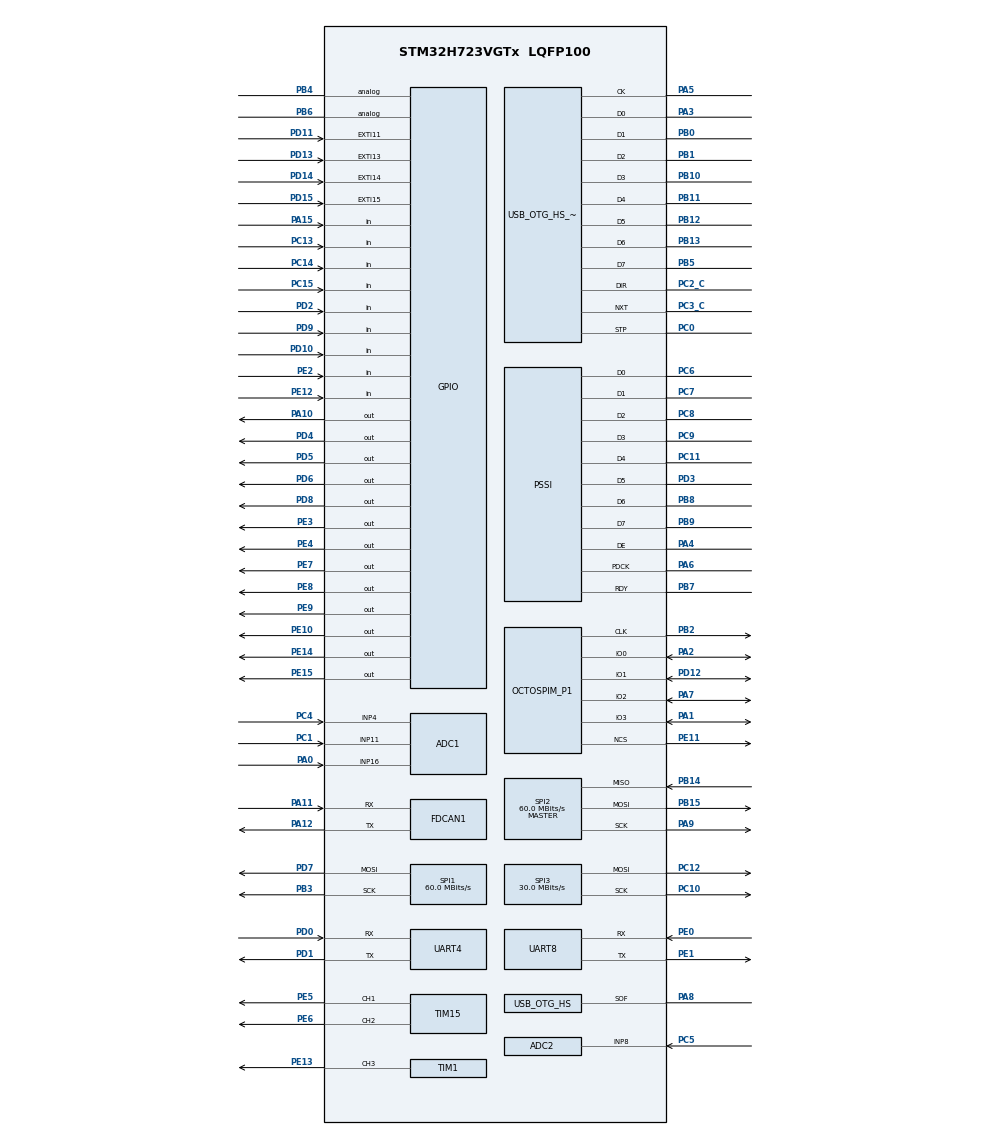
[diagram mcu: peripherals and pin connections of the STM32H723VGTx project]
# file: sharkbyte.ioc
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ADC1.Channel-0\#ChannelRegularConversion=ADC_CHANNEL_4
ADC1.ClockPrescaler=ADC_CLOCK_ASYNC_DIV4
ADC1.ExternalTrigConv=ADC_EXTERNALTRIG_T1_TRGO
ADC1.NbrOfConversionFlag=1
ADC1.OffsetNumber-0\#ChannelRegularConversion=ADC_OFFSET_NONE
ADC1.OffsetSignedSaturation-0\#ChannelRegularConversion=DISABLE
ADC1.Rank-0\#ChannelRegularConversion=1
ADC1.SamplingTime-0\#ChannelRegularConversion=ADC_SAMPLETIME_1CYCLE_5
ADC1.master=1
ADC2.Channel-3\#ChannelRegularConversion=ADC_CHANNEL_8
ADC2.ClockPrescaler=ADC_CLOCK_ASYNC_DIV4
ADC2.ExternalTrigConv=ADC_EXTERNALTRIG_T1_TRGO
ADC2.NbrOfConversionFlag=1
ADC2.OffsetNumber-3\#ChannelRegularConversion=ADC_OFFSET_NONE
ADC2.OffsetSignedSaturation-3\#ChannelRegularConversion=DISABLE
ADC2.Rank-3\#ChannelRegularConversion=1
ADC2.SamplingTime-3\#ChannelRegularConversion=ADC_SAMPLETIME_1CYCLE_5
CORTEX_M7.default_mode_Activation=1
Dma.ADC1.0.Direction=DMA_PERIPH_TO_MEMORY
Dma.ADC1.0.EventEnable=DISABLE
Dma.ADC1.0.FIFOMode=DMA_FIFOMODE_DISABLE
Dma.ADC1.0.Instance=DMA1_Stream0
Dma.ADC1.0.MemDataAlignment=DMA_MDATAALIGN_HALFWORD
Dma.ADC1.0.MemInc=DMA_MINC_ENABLE
Dma.ADC1.0.Mode=DMA_CIRCULAR
Dma.ADC1.0.PeriphDataAlignment=DMA_PDATAALIGN_HALFWORD
Dma.ADC1.0.PeriphInc=DMA_PINC_DISABLE
Dma.ADC1.0.Polarity=HAL_DMAMUX_REQ_GEN_RISING
Dma.ADC1.0.Priority=DMA_PRIORITY_HIGH
Dma.ADC1.0.RequestNumber=1
Dma.ADC1.0.SignalID=NONE
Dma.ADC1.0.SyncEnable=DISABLE
Dma.ADC1.0.SyncPolarity=HAL_DMAMUX_SYNC_NO_EVENT
Dma.ADC1.0.SyncRequestNumber=1
Dma.ADC1.0.SyncSignalID=NONE
Dma.Request0=ADC1
Dma.Request1=SPI1_TX
Dma.Request2=SPI2_RX
Dma.Request3=SPI2_TX
Dma.Request4=SPI3_TX
Dma.SPI1_TX.1.Direction=DMA_MEMORY_TO_PERIPH
Dma.SPI1_TX.1.EventEnable=DISABLE
Dma.SPI1_TX.1.FIFOMode=DMA_FIFOMODE_DISABLE
Dma.SPI1_TX.1.Instance=DMA1_Stream1
Dma.SPI1_TX.1.MemDataAlignment=DMA_MDATAALIGN_BYTE
Dma.SPI1_TX.1.MemInc=DMA_MINC_ENABLE
Dma.SPI1_TX.1.Mode=DMA_NORMAL
Dma.SPI1_TX.1.PeriphDataAlignment=DMA_PDATAALIGN_BYTE
Dma.SPI1_TX.1.PeriphInc=DMA_PINC_DISABLE
Dma.SPI1_TX.1.Polarity=HAL_DMAMUX_REQ_GEN_RISING
Dma.SPI1_TX.1.Priority=DMA_PRIORITY_MEDIUM
Dma.SPI1_TX.1.RequestNumber=1
Dma.SPI1_TX.1.SignalID=NONE
Dma.SPI1_TX.1.SyncEnable=DISABLE
Dma.SPI1_TX.1.SyncPolarity=HAL_DMAMUX_SYNC_NO_EVENT
Dma.SPI1_TX.1.SyncRequestNumber=1
Dma.SPI1_TX.1.SyncSignalID=NONE
Dma.SPI2_RX.2.Direction=DMA_PERIPH_TO_MEMORY
Dma.SPI2_RX.2.EventEnable=DISABLE
Dma.SPI2_RX.2.FIFOMode=DMA_FIFOMODE_DISABLE
Dma.SPI2_RX.2.Instance=DMA1_Stream2
Dma.SPI2_RX.2.MemDataAlignment=DMA_MDATAALIGN_BYTE
Dma.SPI2_RX.2.MemInc=DMA_MINC_ENABLE
Dma.SPI2_RX.2.Mode=DMA_NORMAL
Dma.SPI2_RX.2.PeriphDataAlignment=DMA_PDATAALIGN_BYTE
Dma.SPI2_RX.2.PeriphInc=DMA_PINC_DISABLE
Dma.SPI2_RX.2.Polarity=HAL_DMAMUX_REQ_GEN_RISING
Dma.SPI2_RX.2.Priority=DMA_PRIORITY_HIGH
Dma.SPI2_RX.2.RequestNumber=1
Dma.SPI2_RX.2.SignalID=NONE
Dma.SPI2_RX.2.SyncEnable=DISABLE
Dma.SPI2_RX.2.SyncPolarity=HAL_DMAMUX_SYNC_NO_EVENT
Dma.SPI2_RX.2.SyncRequestNumber=1
Dma.SPI2_RX.2.SyncSignalID=NONE
Dma.SPI2_TX.3.Direction=DMA_MEMORY_TO_PERIPH
Dma.SPI2_TX.3.EventEnable=DISABLE
Dma.SPI2_TX.3.FIFOMode=DMA_FIFOMODE_DISABLE
Dma.SPI2_TX.3.Instance=DMA1_Stream3
Dma.SPI2_TX.3.MemDataAlignment=DMA_MDATAALIGN_BYTE
Dma.SPI2_TX.3.MemInc=DMA_MINC_ENABLE
Dma.SPI2_TX.3.Mode=DMA_NORMAL
Dma.SPI2_TX.3.PeriphDataAlignment=DMA_PDATAALIGN_BYTE
Dma.SPI2_TX.3.PeriphInc=DMA_PINC_DISABLE
Dma.SPI2_TX.3.Polarity=HAL_DMAMUX_REQ_GEN_RISING
Dma.SPI2_TX.3.Priority=DMA_PRIORITY_HIGH
Dma.SPI2_TX.3.RequestNumber=1
Dma.SPI2_TX.3.SignalID=NONE
Dma.SPI2_TX.3.SyncEnable=DISABLE
Dma.SPI2_TX.3.SyncPolarity=HAL_DMAMUX_SYNC_NO_EVENT
Dma.SPI2_TX.3.SyncRequestNumber=1
Dma.SPI2_TX.3.SyncSignalID=NONE
Dma.SPI3_TX.4.Direction=DMA_MEMORY_TO_PERIPH
Dma.SPI3_TX.4.EventEnable=DISABLE
Dma.SPI3_TX.4.FIFOMode=DMA_FIFOMODE_DISABLE
Dma.SPI3_TX.4.Instance=DMA1_Stream4
Dma.SPI3_TX.4.MemDataAlignment=DMA_MDATAALIGN_BYTE
Dma.SPI3_TX.4.MemInc=DMA_MINC_ENABLE
Dma.SPI3_TX.4.Mode=DMA_NORMAL
Dma.SPI3_TX.4.PeriphDataAlignment=DMA_PDATAALIGN_BYTE
Dma.SPI3_TX.4.PeriphInc=DMA_PINC_DISABLE
Dma.SPI3_TX.4.Polarity=HAL_DMAMUX_REQ_GEN_RISING
Dma.SPI3_TX.4.Priority=DMA_PRIORITY_LOW
Dma.SPI3_TX.4.RequestNumber=1
Dma.SPI3_TX.4.SignalID=NONE
Dma.SPI3_TX.4.SyncEnable=DISABLE
Dma.SPI3_TX.4.SyncPolarity=HAL_DMAMUX_SYNC_NO_EVENT
Dma.SPI3_TX.4.SyncRequestNumber=1
Dma.SPI3_TX.4.SyncSignalID=NONE
FDCAN1.CalculateBaudRateNominal=2291666
FDCAN1.CalculateTimeBitNominal=436
FDCAN1.CalculateTimeQuantumNominal=145.45454545454547
FREERTOS.Tasks01=defaultTask,24,512,StartDefaultTask,Default,NULL,Dynamic,NULL,NULL;task_Acquisitio,40,1024,StartAcquisition,Default,NULL,Dynamic,NULL,NULL;task_Comms,32,2048,StartComms,Default,NULL,Dynamic,NULL,NULL;task_Control,24,1024,StartControl,Default,NULL,Dynamic,NULL,NULL;task_GUI,8,4096,StartGUI,Default,NULL,Dynamic,NULL,NULL
FREERTOS.configTOTAL_HEAP_SIZE=65536
FREERTOS.configUSE_NEWLIB_REENTRANT=1
Mcu.Family=STM32H7
Mcu.Name=STM32H723VGTx
Mcu.Package=LQFP100
NVIC.DMA1_Stream0_IRQn=true\:5\:0\:false\:false\:true\:true\:false\:true\:true
NVIC.DMA1_Stream1_IRQn=true\:5\:0\:false\:false\:true\:true\:false\:true\:true
NVIC.DMA1_Stream2_IRQn=true\:5\:0\:false\:false\:true\:true\:false\:true\:true
NVIC.DMA1_Stream3_IRQn=true\:5\:0\:false\:false\:true\:true\:false\:true\:true
NVIC.DMA1_Stream4_IRQn=true\:5\:0\:false\:false\:true\:true\:false\:true\:true
NVIC.EXTI15_10_IRQn=true\:5\:0\:false\:false\:true\:true\:true\:true\:true
NVIC.FDCAN1_IT0_IRQn=true\:5\:0\:false\:false\:true\:true\:true\:true\:true
NVIC.OTG_HS_IRQn=true\:5\:0\:false\:false\:true\:true\:false\:true\:true
NVIC.PriorityGroup=NVIC_PRIORITYGROUP_4
NVIC.SPI1_IRQn=true\:5\:0\:false\:false\:true\:true\:false\:true\:true
NVIC.SPI2_IRQn=true\:5\:0\:false\:false\:true\:true\:false\:true\:true
NVIC.SPI3_IRQn=true\:5\:0\:false\:false\:true\:true\:false\:true\:true
NVIC.TIM6_DAC_IRQn=true\:15\:0\:true\:false\:true\:false\:false\:true\:true
NVIC.TIM7_IRQn=true\:5\:0\:false\:false\:true\:true\:true\:true\:true
NVIC.TimeBase=TIM6_DAC_IRQn
NVIC.TimeBaseIP=TIM6
PA0.Mode=IN16-Single-Ended
PA0.Signal=ADC1_INP16
PA1.Mode=OCTOSPI1_IOL_Port1L
PA1.Signal=OCTOSPIM_P1_IO3
PA10.Signal=GPIO_Output
PA11.Mode=FDCAN_Activate
PA11.Signal=FDCAN1_RX
PA12.Mode=FDCAN_Activate
PA12.Signal=FDCAN1_TX
PA13(JTMS/SWDIO).Mode=Serial_Wire
PA13(JTMS/SWDIO).Signal=DEBUG_JTMS-SWDIO
PA14(JTCK/SWCLK).Mode=Serial_Wire
PA14(JTCK/SWCLK).Signal=DEBUG_JTCK-SWCLK
PA15(JTDI).Signal=GPIO_Input
PA2.Mode=OCTOSPI1_IOL_Port1L
PA2.Signal=OCTOSPIM_P1_IO0
PA3.GPIO_Mode=GPIO_MODE_AF_PP
PA3.GPIO_PuPd=GPIO_NOPULL
PA3.GPIO_Speed_Only_High=GPIO_SPEED_FREQ_VERY_HIGH
PA3.Mode=Device_HS
PA3.Signal=USB_OTG_HS_ULPI_D0
PA4.Mode=PSSI_8
PA4.Signal=PSSI_DE
PA5.GPIO_Mode=GPIO_MODE_AF_PP
PA5.GPIO_PuPd=GPIO_NOPULL
PA5.GPIO_Speed_Only_High=GPIO_SPEED_FREQ_VERY_HIGH
PA5.Mode=Device_HS
PA5.Signal=USB_OTG_HS_ULPI_CK
PA6.Mode=PSSI_8
PA6.Signal=PSSI_PDCK
PA7.Mode=OCTOSPI1_IOL_Port1L
PA7.Signal=OCTOSPIM_P1_IO2
PA8.GPIO_Mode=GPIO_MODE_AF_PP
PA8.GPIO_PuPd=GPIO_NOPULL
PA8.GPIO_Speed=GPIO_SPEED_FREQ_VERY_HIGH
PA8.GPIO_Speed_Only_High=GPIO_SPEED_FREQ_VERY_HIGH
PA8.Mode=Activate_SOF_FS
PA8.Signal=USB_OTG_HS_SOF
PA9.Mode=Full_Duplex_Master
PA9.Signal=SPI2_SCK
PB0.GPIO_Mode=GPIO_MODE_AF_PP
PB0.GPIO_PuPd=GPIO_NOPULL
PB0.GPIO_Speed_Only_High=GPIO_SPEED_FREQ_VERY_HIGH
PB0.Mode=Device_HS
PB0.Signal=USB_OTG_HS_ULPI_D1
PB1.GPIO_Mode=GPIO_MODE_AF_PP
PB1.GPIO_PuPd=GPIO_NOPULL
PB1.GPIO_Speed_Only_High=GPIO_SPEED_FREQ_VERY_HIGH
PB1.Mode=Device_HS
PB1.Signal=USB_OTG_HS_ULPI_D2
PB10.GPIO_Mode=GPIO_MODE_AF_PP
PB10.GPIO_PuPd=GPIO_NOPULL
PB10.GPIO_Speed_Only_High=GPIO_SPEED_FREQ_VERY_HIGH
PB10.Mode=Device_HS
PB10.Signal=USB_OTG_HS_ULPI_D3
PB11.GPIO_Mode=GPIO_MODE_AF_PP
PB11.GPIO_PuPd=GPIO_NOPULL
PB11.GPIO_Speed_Only_High=GPIO_SPEED_FREQ_VERY_HIGH
PB11.Mode=Device_HS
PB11.Signal=USB_OTG_HS_ULPI_D4
PB12.GPIO_Mode=GPIO_MODE_AF_PP
PB12.GPIO_PuPd=GPIO_NOPULL
PB12.GPIO_Speed_Only_High=GPIO_SPEED_FREQ_VERY_HIGH
PB12.Mode=Device_HS
PB12.Signal=USB_OTG_HS_ULPI_D5
PB13.GPIO_Mode=GPIO_MODE_AF_PP
PB13.GPIO_PuPd=GPIO_NOPULL
PB13.GPIO_Speed_Only_High=GPIO_SPEED_FREQ_VERY_HIGH
PB13.Mode=Device_HS
PB13.Signal=USB_OTG_HS_ULPI_D6
PB14.Mode=Full_Duplex_Master
PB14.Signal=SPI2_MISO
PB15.Mode=Full_Duplex_Master
PB15.Signal=SPI2_MOSI
PB2.Mode=O1_P1_CLK
PB2.Signal=OCTOSPIM_P1_CLK
PB3(JTDO/TRACESWO).Mode=TX_Only_Simplex_Unidirect_Master
PB3(JTDO/TRACESWO).Signal=SPI1_SCK
PB4(NJTRST).Signal=GPIO_Analog
PB5.GPIO_Mode=GPIO_MODE_AF_PP
PB5.GPIO_PuPd=GPIO_NOPULL
PB5.GPIO_Speed_Only_High=GPIO_SPEED_FREQ_VERY_HIGH
PB5.Mode=Device_HS
PB5.Signal=USB_OTG_HS_ULPI_D7
PB6.Signal=GPIO_Analog
PB7.Mode=PSSI_8
PB7.Signal=PSSI_RDY
PB8.Mode=PSSI_8
PB8.Signal=PSSI_D6
PB9.Mode=PSSI_8
PB9.Signal=PSSI_D7
PC0.GPIO_Mode=GPIO_MODE_AF_PP
PC0.GPIO_PuPd=GPIO_NOPULL
PC0.GPIO_Speed_Only_High=GPIO_SPEED_FREQ_VERY_HIGH
PC0.Mode=Device_HS
PC0.Signal=USB_OTG_HS_ULPI_STP
PC1.Signal=ADCx_INP11
PC10.Mode=TX_Only_Simplex_Unidirect_Master
PC10.Signal=SPI3_SCK
PC11.Mode=PSSI_8
PC11.Signal=PSSI_D4
PC12.Mode=TX_Only_Simplex_Unidirect_Master
PC12.Signal=SPI3_MOSI
PC13.Signal=GPIO_Input
PC14-OSC32_IN.Signal=GPIO_Input
PC15-OSC32_OUT.Signal=GPIO_Input
PC2_C.GPIO_Mode=GPIO_MODE_AF_PP
PC2_C.GPIO_PuPd=GPIO_NOPULL
PC2_C.GPIO_Speed_Only_High=GPIO_SPEED_FREQ_VERY_HIGH
PC2_C.Mode=Device_HS
PC2_C.Signal=USB_OTG_HS_ULPI_DIR
PC3_C.GPIO_Mode=GPIO_MODE_AF_PP
PC3_C.GPIO_PuPd=GPIO_NOPULL
PC3_C.GPIO_Speed_Only_High=GPIO_SPEED_FREQ_VERY_HIGH
PC3_C.Mode=Device_HS
PC3_C.Signal=USB_OTG_HS_ULPI_NXT
PC4.Signal=ADCx_INP4
PC5.Signal=ADCx_INP8
PC6.Mode=PSSI_8
PC6.Signal=PSSI_D0
PC7.Mode=PSSI_8
PC7.Signal=PSSI_D1
PC8.Mode=PSSI_8
PC8.Signal=PSSI_D2
PC9.Mode=PSSI_8
PC9.Signal=PSSI_D3
PD0.Mode=Asynchronous
PD0.Signal=UART4_RX
PD1.Mode=Asynchronous
PD1.Signal=UART4_TX
PD10.Signal=GPIO_Input
PD11.Signal=GPXTI11
PD12.Mode=OCTOSPI1_IOL_Port1L
PD12.Signal=OCTOSPIM_P1_IO1
PD13.GPIO_ModeDefaultEXTI=GPIO_MODE_IT_RISING_FALLING
PD13.Signal=GPXTI13
PD14.GPIO_ModeDefaultEXTI=GPIO_MODE_IT_RISING_FALLING
PD14.Signal=GPXTI14
PD15.GPIO_ModeDefaultEXTI=GPIO_MODE_IT_RISING_FALLING
PD15.Signal=GPXTI15
PD2.Signal=GPIO_Input
PD3.Mode=PSSI_8
PD3.Signal=PSSI_D5
PD4.Signal=GPIO_Output
PD5.Signal=GPIO_Output
PD6.Signal=GPIO_Output
PD7.Mode=TX_Only_Simplex_Unidirect_Master
PD7.Signal=SPI1_MOSI
PD8.Signal=GPIO_Output
PD9.Signal=GPIO_Input
PE0.Mode=Asynchronous
PE0.Signal=UART8_RX
PE1.Mode=Asynchronous
PE1.Signal=UART8_TX
PE10.Signal=GPIO_Output
PE11.Mode=OCTOSPI1_Port1_NCS
PE11.Signal=OCTOSPIM_P1_NCS
PE12.Signal=GPIO_Input
PE13.Signal=S_TIM1_CH3
PE14.Signal=GPIO_Output
PE15.Signal=GPIO_Output
PE2.Signal=GPIO_Input
PE3.Signal=GPIO_Output
PE4.Signal=GPIO_Output
PE5.Signal=S_TIM15_CH1
PE6.Signal=S_TIM15_CH2
PE7.Signal=GPIO_Output
PE8.Signal=GPIO_Output
PE9.Signal=GPIO_Output
PH0-OSC_IN.Mode=HSE-External-Oscillator
PH0-OSC_IN.Signal=RCC_OSC_IN
PH1-OSC_OUT.Mode=HSE-External-Oscillator
PH1-OSC_OUT.Signal=RCC_OSC_OUT
PSSI.BusWidth=HAL_PSSI_8LINES
ProjectManager.HeapSize=0x2000
ProjectManager.StackSize=0x2000
ProjectManager.TargetToolchain=CMake
RCC.ADCFreq_Value=120000000
RCC.APB1Freq_Value=137500000
RCC.APB2Freq_Value=137500000
RCC.APB3Freq_Value=137500000
RCC.APB4Freq_Value=137500000
RCC.CortexFreq_Value=550000000
RCC.D1PPRE=RCC_APB3_DIV2
RCC.D2PPRE1=RCC_APB1_DIV2
RCC.D2PPRE2=RCC_APB2_DIV2
RCC.D3PPRE=RCC_APB4_DIV2
RCC.DIVM1=5
RCC.DIVM2=5
RCC.DIVM3=5
RCC.DIVN1=110
RCC.DIVN2=96
RCC.DIVN3=96
RCC.DIVP1=1
RCC.DIVP2=4
RCC.DIVQ1=5
RCC.DIVQ2=6
RCC.DIVQ3=10
RCC.DIVR2=4
RCC.DIVR3=5
RCC.FMCCLockSelection=RCC_FMCCLKSOURCE_PLL
RCC.HCLKFreq_Value=275000000
RCC.HPRE=RCC_HCLK_DIV2
RCC.HSE_VALUE=25000000
RCC.PLL2FRACN=0
RCC.PLL3FRACN=0
RCC.PLLFRACN=0
RCC.PLLSourceVirtual=RCC_PLLSOURCE_HSE
RCC.QSPICLockSelection=RCC_OSPICLKSOURCE_PLL2
RCC.SPI123CLockSelection=RCC_SPI123CLKSOURCE_PLL2
RCC.SYSCLKFreq_VALUE=550000000
RCC.SYSCLKSource=RCC_SYSCLKSOURCE_PLLCLK
RCC.USART234578CLockSelection=RCC_USART234578CLKSOURCE_PLL2
RCC.USBCLockSelection=RCC_USBCLKSOURCE_PLL3
RCC.USBFreq_Value=48000000
SH.ADCx_INP11.0=ADC1_INP11,IN11-Single-Ended
SH.ADCx_INP4.0=ADC1_INP4,IN4-Single-Ended
SH.ADCx_INP8.0=ADC2_INP8,IN8-Single-Ended
SH.S_TIM15_CH1.0=TIM15_CH1,PWM Generation1 CH1
SH.S_TIM15_CH2.0=TIM15_CH2,PWM Generation2 CH2
SH.S_TIM1_CH3.0=TIM1_CH3,PWM Generation3 CH3
SPI1.BaudRatePrescaler=SPI_BAUDRATEPRESCALER_2
SPI1.CalculateBaudRate=60.0 MBits/s
SPI1.Direction=SPI_DIRECTION_2LINES_TXONLY
SPI1.Mode=SPI_MODE_MASTER
SPI1.VirtualType=VM_MASTER
SPI2.BaudRatePrescaler=SPI_BAUDRATEPRESCALER_2
SPI2.CalculateBaudRate=60.0 MBits/s
SPI2.Direction=SPI_DIRECTION_2LINES
SPI2.Mode=SPI_MODE_MASTER
SPI2.VirtualType=VM_MASTER
SPI3.BaudRatePrescaler=SPI_BAUDRATEPRESCALER_4
SPI3.CLKPolarity=SPI_POLARITY_HIGH
SPI3.CalculateBaudRate=30.0 MBits/s
SPI3.DataSize=SPI_DATASIZE_8BIT
SPI3.Direction=SPI_DIRECTION_2LINES_TXONLY
SPI3.Mode=SPI_MODE_MASTER
SPI3.NSSPMode=SPI_NSS_PULSE_DISABLE
SPI3.VirtualType=VM_MASTER
TIM1.Channel-PWM\ Generation3\ CH3=TIM_CHANNEL_3
TIM1.TIM_MasterOutputTrigger=TIM_TRGO_UPDATE
TIM15.Channel-PWM\ Generation1\ CH1=TIM_CHANNEL_1
TIM15.Channel-PWM\ Generation2\ CH2=TIM_CHANNEL_2
USB_DEVICE.CLASS_NAME_HS=CDC
USB_DEVICE.USBD_DEBUG_LEVEL=0
USB_DEVICE.VirtualMode=Cdc
USB_DEVICE.VirtualModeHS=Cdc_HS
USB_OTG_HS.VirtualMode-Device_HS=Device_HS
USB_OTG_HS.VirtualMode-Host_HS=Host_HS
VP_FREERTOS_VS_CMSIS_V2.Mode=CMSIS_V2
VP_MEMORYMAP_VS_MEMORYMAP.Mode=CurAppReg
VP_OCTOSPI1_VS_octo.Mode=octo_mode
VP_SYS_VS_tim6.Mode=TIM6
VP_TIM7_VS_ClockSourceINT.Mode=Enable_Timer
VP_USB_DEVICE_VS_USB_DEVICE_CDC_HS.Mode=CDC_HS
board=custom

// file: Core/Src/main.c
/* USER CODE BEGIN Header */
/**
  ******************************************************************************
  * @file           : main.c
  * @brief          : Main program body
  ******************************************************************************
  * @attention
  *
  * Copyright (c) 2026 STMicroelectronics.
  * All rights reserved.
  *
  * This software is licensed under terms that can be found in the LICENSE file
  * in the root directory of this software component.
  * If no LICENSE file comes with this software, it is provided AS-IS.
  *
  ******************************************************************************
  */
/* USER CODE END Header */
#include "main.h"
#include "cmsis_os.h"

/* USER CODE BEGIN Includes */
#include "board.h"
#include <stdint.h>
#include <stdio.h>
#include <string.h>
#include "gui.h"
/* USER CODE END Includes */

ADC_HandleTypeDef hadc1;
ADC_HandleTypeDef hadc2;
DMA_HandleTypeDef hdma_adc1;

FDCAN_HandleTypeDef hfdcan1;

OSPI_HandleTypeDef hospi1;

PSSI_HandleTypeDef hpssi;

SPI_HandleTypeDef hspi1;
SPI_HandleTypeDef hspi2;
SPI_HandleTypeDef hspi3;
DMA_HandleTypeDef hdma_spi1_tx;
DMA_HandleTypeDef hdma_spi2_rx;
DMA_HandleTypeDef hdma_spi2_tx;
DMA_HandleTypeDef hdma_spi3_tx;

TIM_HandleTypeDef htim1;
TIM_HandleTypeDef htim7;
TIM_HandleTypeDef htim15;

UART_HandleTypeDef huart4;
UART_HandleTypeDef huart8;

/* Definitions for defaultTask */
osThreadId_t defaultTaskHandle;
const osThreadAttr_t defaultTask_attributes = {
  .name = "defaultTask",
  .stack_size = 512 * 4,
  .priority = (osPriority_t) osPriorityNormal,
};
/* Definitions for task_Acquisitio */
osThreadId_t task_AcquisitioHandle;
const osThreadAttr_t task_Acquisitio_attributes = {
  .name = "task_Acquisitio",
  .stack_size = 1024 * 4,
  .priority = (osPriority_t) osPriorityHigh,
};
/* Definitions for task_Comms */
osThreadId_t task_CommsHandle;
const osThreadAttr_t task_Comms_attributes = {
  .name = "task_Comms",
  .stack_size = 2048 * 4,
  .priority = (osPriority_t) osPriorityAboveNormal,
};
/* Definitions for task_Control */
osThreadId_t task_ControlHandle;
const osThreadAttr_t task_Control_attributes = {
  .name = "task_Control",
  .stack_size = 1024 * 4,
  .priority = (osPriority_t) osPriorityNormal,
};
/* Definitions for task_GUI */
osThreadId_t task_GUIHandle;
const osThreadAttr_t task_GUI_attributes = {
  .name = "task_GUI",
  .stack_size = 4096 * 4,
  .priority = (osPriority_t) osPriorityLow,
};

void SystemClock_Config(void);
void PeriphCommonClock_Config(void);
static void MPU_Config(void);
static void MX_GPIO_Init(void);
static void MX_DMA_Init(void);
static void MX_PSSI_Init(void);
static void MX_ADC1_Init(void);
static void MX_ADC2_Init(void);
static void MX_SPI1_Init(void);
static void MX_SPI2_Init(void);
static void MX_SPI3_Init(void);
static void MX_TIM1_Init(void);
static void MX_UART8_Init(void);
static void MX_FDCAN1_Init(void);
static void MX_TIM15_Init(void);
static void MX_UART4_Init(void);
static void MX_OCTOSPI1_Init(void);
static void MX_TIM7_Init(void);
void StartDefaultTask(void *argument);
void StartAcquisition(void *argument);
void StartComms(void *argument);
void StartControl(void *argument);
void StartGUI(void *argument);

int main(void)
{

  /* MPU Configuration--------------------------------------------------------*/
  MPU_Config();

  /* MCU Configuration--------------------------------------------------------*/

  /* Reset of all peripherals, Initializes the Flash interface and the Systick. */
  HAL_Init();

  /* Configure the system clock */
  SystemClock_Config();

  /* Configure the peripherals common clocks */
  PeriphCommonClock_Config();

  /* Initialize all configured peripherals */
  MX_GPIO_Init();
  MX_DMA_Init();
  MX_PSSI_Init();
  MX_ADC1_Init();
  MX_ADC2_Init();
  MX_SPI1_Init();
  MX_SPI2_Init();
  MX_SPI3_Init();
  MX_TIM1_Init();
  MX_UART8_Init();
  MX_FDCAN1_Init();
  MX_TIM15_Init();
  MX_UART4_Init();
  MX_OCTOSPI1_Init();
  MX_TIM7_Init();

  /* Init scheduler */
  osKernelInitialize();

  /* Create the thread(s) */
  /* creation of defaultTask */
  defaultTaskHandle = osThreadNew(StartDefaultTask, NULL, &defaultTask_attributes);

  /* creation of task_Acquisitio */
  task_AcquisitioHandle = osThreadNew(StartAcquisition, NULL, &task_Acquisitio_attributes);

  /* creation of task_Comms */
  task_CommsHandle = osThreadNew(StartComms, NULL, &task_Comms_attributes);

  /* creation of task_Control */
  task_ControlHandle = osThreadNew(StartControl, NULL, &task_Control_attributes);

  /* creation of task_GUI */
  task_GUIHandle = osThreadNew(StartGUI, NULL, &task_GUI_attributes);

  /* Start scheduler */
  osKernelStart();

  /* We should never get here as control is now taken by the scheduler */

  /* Infinite loop */
  while (1)
  {

  }
}

void SystemClock_Config(void)
{
  RCC_OscInitTypeDef RCC_OscInitStruct = {0};
  RCC_ClkInitTypeDef RCC_ClkInitStruct = {0};

  /** Supply configuration update enable
  */
  HAL_PWREx_ConfigSupply(PWR_LDO_SUPPLY);

  /** Configure the main internal regulator output voltage
  */
  __HAL_PWR_VOLTAGESCALING_CONFIG(PWR_REGULATOR_VOLTAGE_SCALE0);

  while(!__HAL_PWR_GET_FLAG(PWR_FLAG_VOSRDY)) {}

  /** Initializes the RCC Oscillators according to the specified parameters
  * in the RCC_OscInitTypeDef structure.
  */
  RCC_OscInitStruct.OscillatorType = RCC_OSCILLATORTYPE_HSE;
  RCC_OscInitStruct.HSEState = RCC_HSE_ON;
  RCC_OscInitStruct.PLL.PLLState = RCC_PLL_ON;
  RCC_OscInitStruct.PLL.PLLSource = RCC_PLLSOURCE_HSE;
  RCC_OscInitStruct.PLL.PLLM = 5;
  RCC_OscInitStruct.PLL.PLLN = 110;
  RCC_OscInitStruct.PLL.PLLP = 1;
  RCC_OscInitStruct.PLL.PLLQ = 5;
  RCC_OscInitStruct.PLL.PLLR = 2;
  RCC_OscInitStruct.PLL.PLLRGE = RCC_PLL1VCIRANGE_2;
  RCC_OscInitStruct.PLL.PLLVCOSEL = RCC_PLL1VCOWIDE;
  RCC_OscInitStruct.PLL.PLLFRACN = 0;
  if (HAL_RCC_OscConfig(&RCC_OscInitStruct) != HAL_OK)
  {
    Error_Handler();
  }

  /** Initializes the CPU, AHB and APB buses clocks
  */
  RCC_ClkInitStruct.ClockType = RCC_CLOCKTYPE_HCLK|RCC_CLOCKTYPE_SYSCLK
                              |RCC_CLOCKTYPE_PCLK1|RCC_CLOCKTYPE_PCLK2
                              |RCC_CLOCKTYPE_D3PCLK1|RCC_CLOCKTYPE_D1PCLK1;
  RCC_ClkInitStruct.SYSCLKSource = RCC_SYSCLKSOURCE_PLLCLK;
  RCC_ClkInitStruct.SYSCLKDivider = RCC_SYSCLK_DIV1;
  RCC_ClkInitStruct.AHBCLKDivider = RCC_HCLK_DIV2;
  RCC_ClkInitStruct.APB3CLKDivider = RCC_APB3_DIV2;
  RCC_ClkInitStruct.APB1CLKDivider = RCC_APB1_DIV2;
  RCC_ClkInitStruct.APB2CLKDivider = RCC_APB2_DIV2;
  RCC_ClkInitStruct.APB4CLKDivider = RCC_APB4_DIV2;

  if (HAL_RCC_ClockConfig(&RCC_ClkInitStruct, FLASH_LATENCY_3) != HAL_OK)
  {
    Error_Handler();
  }
}

void PeriphCommonClock_Config(void)
{
  RCC_PeriphCLKInitTypeDef PeriphClkInitStruct = {0};

  /** Initializes the peripherals clock
  */
  PeriphClkInitStruct.PeriphClockSelection = RCC_PERIPHCLK_OSPI|RCC_PERIPHCLK_ADC
                              |RCC_PERIPHCLK_SPI3|RCC_PERIPHCLK_SPI2
                              |RCC_PERIPHCLK_SPI1|RCC_PERIPHCLK_UART8
                              |RCC_PERIPHCLK_UART4;
  PeriphClkInitStruct.PLL2.PLL2M = 5;
  PeriphClkInitStruct.PLL2.PLL2N = 96;
  PeriphClkInitStruct.PLL2.PLL2P = 4;
  PeriphClkInitStruct.PLL2.PLL2Q = 6;
  PeriphClkInitStruct.PLL2.PLL2R = 4;
  PeriphClkInitStruct.PLL2.PLL2RGE = RCC_PLL2VCIRANGE_2;
  PeriphClkInitStruct.PLL2.PLL2VCOSEL = RCC_PLL2VCOWIDE;
  PeriphClkInitStruct.PLL2.PLL2FRACN = 0;
  PeriphClkInitStruct.OspiClockSelection = RCC_OSPICLKSOURCE_PLL2;
  PeriphClkInitStruct.Spi123ClockSelection = RCC_SPI123CLKSOURCE_PLL2;
  PeriphClkInitStruct.Usart234578ClockSelection = RCC_USART234578CLKSOURCE_PLL2;
  PeriphClkInitStruct.AdcClockSelection = RCC_ADCCLKSOURCE_PLL2;
  if (HAL_RCCEx_PeriphCLKConfig(&PeriphClkInitStruct) != HAL_OK)
  {
    Error_Handler();
  }
}

static void MX_ADC1_Init(void)
{

  ADC_MultiModeTypeDef multimode = {0};
  ADC_ChannelConfTypeDef sConfig = {0};

  /** Common config
  */
  hadc1.Instance = ADC1;
  hadc1.Init.ClockPrescaler = ADC_CLOCK_ASYNC_DIV4;
  hadc1.Init.Resolution = ADC_RESOLUTION_16B;
  hadc1.Init.ScanConvMode = ADC_SCAN_DISABLE;
  hadc1.Init.EOCSelection = ADC_EOC_SINGLE_CONV;
  hadc1.Init.LowPowerAutoWait = DISABLE;
  hadc1.Init.ContinuousConvMode = DISABLE;
  hadc1.Init.NbrOfConversion = 1;
  hadc1.Init.DiscontinuousConvMode = DISABLE;
  hadc1.Init.ExternalTrigConv = ADC_EXTERNALTRIG_T1_TRGO;
  hadc1.Init.ExternalTrigConvEdge = ADC_EXTERNALTRIGCONVEDGE_RISING;
  hadc1.Init.ConversionDataManagement = ADC_CONVERSIONDATA_DR;
  hadc1.Init.Overrun = ADC_OVR_DATA_PRESERVED;
  hadc1.Init.LeftBitShift = ADC_LEFTBITSHIFT_NONE;
  hadc1.Init.OversamplingMode = DISABLE;
  hadc1.Init.Oversampling.Ratio = 1;
  if (HAL_ADC_Init(&hadc1) != HAL_OK)
  {
    Error_Handler();
  }

  /** Configure the ADC multi-mode
  */
  multimode.Mode = ADC_MODE_INDEPENDENT;
  if (HAL_ADCEx_MultiModeConfigChannel(&hadc1, &multimode) != HAL_OK)
  {
    Error_Handler();
  }

  /** Configure Regular Channel
  */
  sConfig.Channel = ADC_CHANNEL_4;
  sConfig.Rank = ADC_REGULAR_RANK_1;
  sConfig.SamplingTime = ADC_SAMPLETIME_1CYCLE_5;
  sConfig.SingleDiff = ADC_SINGLE_ENDED;
  sConfig.OffsetNumber = ADC_OFFSET_NONE;
  sConfig.Offset = 0;
  sConfig.OffsetSignedSaturation = DISABLE;
  if (HAL_ADC_ConfigChannel(&hadc1, &sConfig) != HAL_OK)
  {
    Error_Handler();
  }

}

static void MX_ADC2_Init(void)
{

  ADC_ChannelConfTypeDef sConfig = {0};

  /** Common config
  */
  hadc2.Instance = ADC2;
  hadc2.Init.ClockPrescaler = ADC_CLOCK_ASYNC_DIV4;
  hadc2.Init.Resolution = ADC_RESOLUTION_16B;
  hadc2.Init.ScanConvMode = ADC_SCAN_DISABLE;
  hadc2.Init.EOCSelection = ADC_EOC_SINGLE_CONV;
  hadc2.Init.LowPowerAutoWait = DISABLE;
  hadc2.Init.ContinuousConvMode = DISABLE;
  hadc2.Init.NbrOfConversion = 1;
  hadc2.Init.DiscontinuousConvMode = DISABLE;
  hadc2.Init.ExternalTrigConv = ADC_EXTERNALTRIG_T1_TRGO;
  hadc2.Init.ExternalTrigConvEdge = ADC_EXTERNALTRIGCONVEDGE_RISING;
  hadc2.Init.ConversionDataManagement = ADC_CONVERSIONDATA_DR;
  hadc2.Init.Overrun = ADC_OVR_DATA_PRESERVED;
  hadc2.Init.LeftBitShift = ADC_LEFTBITSHIFT_NONE;
  hadc2.Init.OversamplingMode = DISABLE;
  hadc2.Init.Oversampling.Ratio = 1;
  if (HAL_ADC_Init(&hadc2) != HAL_OK)
  {
    Error_Handler();
  }

  /** Configure Regular Channel
  */
  sConfig.Channel = ADC_CHANNEL_8;
  sConfig.Rank = ADC_REGULAR_RANK_1;
  sConfig.SamplingTime = ADC_SAMPLETIME_1CYCLE_5;
  sConfig.SingleDiff = ADC_SINGLE_ENDED;
  sConfig.OffsetNumber = ADC_OFFSET_NONE;
  sConfig.Offset = 0;
  sConfig.OffsetSignedSaturation = DISABLE;
  if (HAL_ADC_ConfigChannel(&hadc2, &sConfig) != HAL_OK)
  {
    Error_Handler();
  }

}

static void MX_FDCAN1_Init(void)
{

  hfdcan1.Instance = FDCAN1;
  hfdcan1.Init.FrameFormat = FDCAN_FRAME_CLASSIC;
  hfdcan1.Init.Mode = FDCAN_MODE_NORMAL;
  hfdcan1.Init.AutoRetransmission = DISABLE;
  hfdcan1.Init.TransmitPause = DISABLE;
  hfdcan1.Init.ProtocolException = DISABLE;
  hfdcan1.Init.NominalPrescaler = 16;
  hfdcan1.Init.NominalSyncJumpWidth = 1;
  hfdcan1.Init.NominalTimeSeg1 = 1;
  hfdcan1.Init.NominalTimeSeg2 = 1;
  hfdcan1.Init.DataPrescaler = 1;
  hfdcan1.Init.DataSyncJumpWidth = 1;
  hfdcan1.Init.DataTimeSeg1 = 1;
  hfdcan1.Init.DataTimeSeg2 = 1;
  hfdcan1.Init.MessageRAMOffset = 0;
  hfdcan1.Init.StdFiltersNbr = 0;
  hfdcan1.Init.ExtFiltersNbr = 0;
  hfdcan1.Init.RxFifo0ElmtsNbr = 0;
  hfdcan1.Init.RxFifo0ElmtSize = FDCAN_DATA_BYTES_8;
  hfdcan1.Init.RxFifo1ElmtsNbr = 0;
  hfdcan1.Init.RxFifo1ElmtSize = FDCAN_DATA_BYTES_8;
  hfdcan1.Init.RxBuffersNbr = 0;
  hfdcan1.Init.RxBufferSize = FDCAN_DATA_BYTES_8;
  hfdcan1.Init.TxEventsNbr = 0;
  hfdcan1.Init.TxBuffersNbr = 0;
  hfdcan1.Init.TxFifoQueueElmtsNbr = 0;
  hfdcan1.Init.TxFifoQueueMode = FDCAN_TX_FIFO_OPERATION;
  hfdcan1.Init.TxElmtSize = FDCAN_DATA_BYTES_8;
  if (HAL_FDCAN_Init(&hfdcan1) != HAL_OK)
  {
    Error_Handler();
  }

}

static void MX_OCTOSPI1_Init(void)
{

  OSPIM_CfgTypeDef sOspiManagerCfg = {0};

  /* OCTOSPI1 parameter configuration*/
  hospi1.Instance = OCTOSPI1;
  hospi1.Init.FifoThreshold = 1;
  hospi1.Init.DualQuad = HAL_OSPI_DUALQUAD_DISABLE;
  hospi1.Init.MemoryType = HAL_OSPI_MEMTYPE_MICRON;
  hospi1.Init.DeviceSize = 32;
  hospi1.Init.ChipSelectHighTime = 1;
  hospi1.Init.FreeRunningClock = HAL_OSPI_FREERUNCLK_DISABLE;
  hospi1.Init.ClockMode = HAL_OSPI_CLOCK_MODE_0;
  hospi1.Init.WrapSize = HAL_OSPI_WRAP_NOT_SUPPORTED;
  hospi1.Init.ClockPrescaler = 1;
  hospi1.Init.SampleShifting = HAL_OSPI_SAMPLE_SHIFTING_NONE;
  hospi1.Init.DelayHoldQuarterCycle = HAL_OSPI_DHQC_DISABLE;
  hospi1.Init.ChipSelectBoundary = 0;
  hospi1.Init.DelayBlockBypass = HAL_OSPI_DELAY_BLOCK_BYPASSED;
  hospi1.Init.MaxTran = 0;
  hospi1.Init.Refresh = 0;
  if (HAL_OSPI_Init(&hospi1) != HAL_OK)
  {
    Error_Handler();
  }
  sOspiManagerCfg.ClkPort = 1;
  sOspiManagerCfg.NCSPort = 1;
  sOspiManagerCfg.IOLowPort = HAL_OSPIM_IOPORT_1_LOW;
  if (HAL_OSPIM_Config(&hospi1, &sOspiManagerCfg, HAL_OSPI_TIMEOUT_DEFAULT_VALUE) != HAL_OK)
  {
    Error_Handler();
  }

}

static void MX_PSSI_Init(void)
{

  hpssi.Instance = PSSI;
  hpssi.Init.DataWidth = HAL_PSSI_8BITS;
  hpssi.Init.BusWidth = HAL_PSSI_8LINES;
  hpssi.Init.ControlSignal = HAL_PSSI_DE_RDY_DISABLE;
  hpssi.Init.ClockPolarity = HAL_PSSI_FALLING_EDGE;
  hpssi.Init.DataEnablePolarity = HAL_PSSI_DEPOL_ACTIVE_LOW;
  hpssi.Init.ReadyPolarity = HAL_PSSI_RDYPOL_ACTIVE_LOW;
  if (HAL_PSSI_Init(&hpssi) != HAL_OK)
  {
    Error_Handler();
  }

}

static void MX_SPI1_Init(void)
{

  /* SPI1 parameter configuration*/
  hspi1.Instance = SPI1;
  hspi1.Init.Mode = SPI_MODE_MASTER;
  hspi1.Init.Direction = SPI_DIRECTION_2LINES_TXONLY;
  hspi1.Init.DataSize = SPI_DATASIZE_4BIT;
  hspi1.Init.CLKPolarity = SPI_POLARITY_LOW;
  hspi1.Init.CLKPhase = SPI_PHASE_1EDGE;
  hspi1.Init.NSS = SPI_NSS_SOFT;
  hspi1.Init.BaudRatePrescaler = SPI_BAUDRATEPRESCALER_2;
  hspi1.Init.FirstBit = SPI_FIRSTBIT_MSB;
  hspi1.Init.TIMode = SPI_TIMODE_DISABLE;
  hspi1.Init.CRCCalculation = SPI_CRCCALCULATION_DISABLE;
  hspi1.Init.CRCPolynomial = 0x0;
  hspi1.Init.NSSPMode = SPI_NSS_PULSE_ENABLE;
  hspi1.Init.NSSPolarity = SPI_NSS_POLARITY_LOW;
  hspi1.Init.FifoThreshold = SPI_FIFO_THRESHOLD_01DATA;
  hspi1.Init.TxCRCInitializationPattern = SPI_CRC_INITIALIZATION_ALL_ZERO_PATTERN;
  hspi1.Init.RxCRCInitializationPattern = SPI_CRC_INITIALIZATION_ALL_ZERO_PATTERN;
  hspi1.Init.MasterSSIdleness = SPI_MASTER_SS_IDLENESS_00CYCLE;
  hspi1.Init.MasterInterDataIdleness = SPI_MASTER_INTERDATA_IDLENESS_00CYCLE;
  hspi1.Init.MasterReceiverAutoSusp = SPI_MASTER_RX_AUTOSUSP_DISABLE;
  hspi1.Init.MasterKeepIOState = SPI_MASTER_KEEP_IO_STATE_DISABLE;
  hspi1.Init.IOSwap = SPI_IO_SWAP_DISABLE;
  if (HAL_SPI_Init(&hspi1) != HAL_OK)
  {
    Error_Handler();
  }

}

static void MX_SPI2_Init(void)
{

  /* SPI2 parameter configuration*/
  hspi2.Instance = SPI2;
  hspi2.Init.Mode = SPI_MODE_MASTER;
  hspi2.Init.Direction = SPI_DIRECTION_2LINES;
  hspi2.Init.DataSize = SPI_DATASIZE_4BIT;
  hspi2.Init.CLKPolarity = SPI_POLARITY_LOW;
  hspi2.Init.CLKPhase = SPI_PHASE_1EDGE;
  hspi2.Init.NSS = SPI_NSS_SOFT;
  hspi2.Init.BaudRatePrescaler = SPI_BAUDRATEPRESCALER_2;
  hspi2.Init.FirstBit = SPI_FIRSTBIT_MSB;
  hspi2.Init.TIMode = SPI_TIMODE_DISABLE;
  hspi2.Init.CRCCalculation = SPI_CRCCALCULATION_DISABLE;
  hspi2.Init.CRCPolynomial = 0x0;
  hspi2.Init.NSSPMode = SPI_NSS_PULSE_ENABLE;
  hspi2.Init.NSSPolarity = SPI_NSS_POLARITY_LOW;
  hspi2.Init.FifoThreshold = SPI_FIFO_THRESHOLD_01DATA;
  hspi2.Init.TxCRCInitializationPattern = SPI_CRC_INITIALIZATION_ALL_ZERO_PATTERN;
  hspi2.Init.RxCRCInitializationPattern = SPI_CRC_INITIALIZATION_ALL_ZERO_PATTERN;
  hspi2.Init.MasterSSIdleness = SPI_MASTER_SS_IDLENESS_00CYCLE;
  hspi2.Init.MasterInterDataIdleness = SPI_MASTER_INTERDATA_IDLENESS_00CYCLE;
  hspi2.Init.MasterReceiverAutoSusp = SPI_MASTER_RX_AUTOSUSP_DISABLE;
  hspi2.Init.MasterKeepIOState = SPI_MASTER_KEEP_IO_STATE_DISABLE;
  hspi2.Init.IOSwap = SPI_IO_SWAP_DISABLE;
  if (HAL_SPI_Init(&hspi2) != HAL_OK)
  {
    Error_Handler();
  }

}

static void MX_SPI3_Init(void)
{

  /* SPI3 parameter configuration*/
  hspi3.Instance = SPI3;
  hspi3.Init.Mode = SPI_MODE_MASTER;
  hspi3.Init.Direction = SPI_DIRECTION_2LINES_TXONLY;
  hspi3.Init.DataSize = SPI_DATASIZE_8BIT;
  hspi3.Init.CLKPolarity = SPI_POLARITY_HIGH;
  hspi3.Init.CLKPhase = SPI_PHASE_1EDGE;
  hspi3.Init.NSS = SPI_NSS_SOFT;
  hspi3.Init.BaudRatePrescaler = SPI_BAUDRATEPRESCALER_4;
  hspi3.Init.FirstBit = SPI_FIRSTBIT_MSB;
  hspi3.Init.TIMode = SPI_TIMODE_DISABLE;
  hspi3.Init.CRCCalculation = SPI_CRCCALCULATION_DISABLE;
  hspi3.Init.CRCPolynomial = 0x0;
  hspi3.Init.NSSPMode = SPI_NSS_PULSE_DISABLE;
  hspi3.Init.NSSPolarity = SPI_NSS_POLARITY_LOW;
  hspi3.Init.FifoThreshold = SPI_FIFO_THRESHOLD_01DATA;
  hspi3.Init.TxCRCInitializationPattern = SPI_CRC_INITIALIZATION_ALL_ZERO_PATTERN;
  hspi3.Init.RxCRCInitializationPattern = SPI_CRC_INITIALIZATION_ALL_ZERO_PATTERN;
  hspi3.Init.MasterSSIdleness = SPI_MASTER_SS_IDLENESS_00CYCLE;
  hspi3.Init.MasterInterDataIdleness = SPI_MASTER_INTERDATA_IDLENESS_00CYCLE;
  hspi3.Init.MasterReceiverAutoSusp = SPI_MASTER_RX_AUTOSUSP_DISABLE;
  hspi3.Init.MasterKeepIOState = SPI_MASTER_KEEP_IO_STATE_DISABLE;
  hspi3.Init.IOSwap = SPI_IO_SWAP_DISABLE;
  if (HAL_SPI_Init(&hspi3) != HAL_OK)
  {
    Error_Handler();
  }

}

static void MX_TIM1_Init(void)
{

  TIM_MasterConfigTypeDef sMasterConfig = {0};
  TIM_OC_InitTypeDef sConfigOC = {0};
  TIM_BreakDeadTimeConfigTypeDef sBreakDeadTimeConfig = {0};

  htim1.Instance = TIM1;
  htim1.Init.Prescaler = 0;
  htim1.Init.CounterMode = TIM_COUNTERMODE_UP;
  htim1.Init.Period = 65535;
  htim1.Init.ClockDivision = TIM_CLOCKDIVISION_DIV1;
  htim1.Init.RepetitionCounter = 0;
  htim1.Init.AutoReloadPreload = TIM_AUTORELOAD_PRELOAD_DISABLE;
  if (HAL_TIM_PWM_Init(&htim1) != HAL_OK)
  {
    Error_Handler();
  }
  sMasterConfig.MasterOutputTrigger = TIM_TRGO_UPDATE;
  sMasterConfig.MasterOutputTrigger2 = TIM_TRGO2_RESET;
  sMasterConfig.MasterSlaveMode = TIM_MASTERSLAVEMODE_DISABLE;
  if (HAL_TIMEx_MasterConfigSynchronization(&htim1, &sMasterConfig) != HAL_OK)
  {
    Error_Handler();
  }
  sConfigOC.OCMode = TIM_OCMODE_PWM1;
  sConfigOC.Pulse = 0;
  sConfigOC.OCPolarity = TIM_OCPOLARITY_HIGH;
  sConfigOC.OCNPolarity = TIM_OCNPOLARITY_HIGH;
  sConfigOC.OCFastMode = TIM_OCFAST_DISABLE;
  sConfigOC.OCIdleState = TIM_OCIDLESTATE_RESET;
  sConfigOC.OCNIdleState = TIM_OCNIDLESTATE_RESET;
  if (HAL_TIM_PWM_ConfigChannel(&htim1, &sConfigOC, TIM_CHANNEL_3) != HAL_OK)
  {
    Error_Handler();
  }
  sBreakDeadTimeConfig.OffStateRunMode = TIM_OSSR_DISABLE;
  sBreakDeadTimeConfig.OffStateIDLEMode = TIM_OSSI_DISABLE;
  sBreakDeadTimeConfig.LockLevel = TIM_LOCKLEVEL_OFF;
  sBreakDeadTimeConfig.DeadTime = 0;
  sBreakDeadTimeConfig.BreakState = TIM_BREAK_DISABLE;
  sBreakDeadTimeConfig.BreakPolarity = TIM_BREAKPOLARITY_HIGH;
  sBreakDeadTimeConfig.BreakFilter = 0;
  sBreakDeadTimeConfig.Break2State = TIM_BREAK2_DISABLE;
  sBreakDeadTimeConfig.Break2Polarity = TIM_BREAK2POLARITY_HIGH;
  sBreakDeadTimeConfig.Break2Filter = 0;
  sBreakDeadTimeConfig.AutomaticOutput = TIM_AUTOMATICOUTPUT_DISABLE;
  if (HAL_TIMEx_ConfigBreakDeadTime(&htim1, &sBreakDeadTimeConfig) != HAL_OK)
  {
    Error_Handler();
  }
  HAL_TIM_MspPostInit(&htim1);

}

static void MX_TIM7_Init(void)
{

  TIM_MasterConfigTypeDef sMasterConfig = {0};

  htim7.Instance = TIM7;
  htim7.Init.Prescaler = 0;
  htim7.Init.CounterMode = TIM_COUNTERMODE_UP;
  htim7.Init.Period = 65535;
  htim7.Init.AutoReloadPreload = TIM_AUTORELOAD_PRELOAD_DISABLE;
  if (HAL_TIM_Base_Init(&htim7) != HAL_OK)
  {
    Error_Handler();
  }
  sMasterConfig.MasterOutputTrigger = TIM_TRGO_RESET;
  sMasterConfig.MasterSlaveMode = TIM_MASTERSLAVEMODE_DISABLE;
  if (HAL_TIMEx_MasterConfigSynchronization(&htim7, &sMasterConfig) != HAL_OK)
  {
    Error_Handler();
  }

}

static void MX_TIM15_Init(void)
{

  TIM_MasterConfigTypeDef sMasterConfig = {0};
  TIM_OC_InitTypeDef sConfigOC = {0};
  TIM_BreakDeadTimeConfigTypeDef sBreakDeadTimeConfig = {0};

  htim15.Instance = TIM15;
  htim15.Init.Prescaler = 0;
  htim15.Init.CounterMode = TIM_COUNTERMODE_UP;
  htim15.Init.Period = 65535;
  htim15.Init.ClockDivision = TIM_CLOCKDIVISION_DIV1;
  htim15.Init.RepetitionCounter = 0;
  htim15.Init.AutoReloadPreload = TIM_AUTORELOAD_PRELOAD_DISABLE;
  if (HAL_TIM_PWM_Init(&htim15) != HAL_OK)
  {
    Error_Handler();
  }
  sMasterConfig.MasterOutputTrigger = TIM_TRGO_RESET;
  sMasterConfig.MasterSlaveMode = TIM_MASTERSLAVEMODE_DISABLE;
  if (HAL_TIMEx_MasterConfigSynchronization(&htim15, &sMasterConfig) != HAL_OK)
  {
    Error_Handler();
  }
  sConfigOC.OCMode = TIM_OCMODE_PWM1;
  sConfigOC.Pulse = 0;
  sConfigOC.OCPolarity = TIM_OCPOLARITY_HIGH;
  sConfigOC.OCNPolarity = TIM_OCNPOLARITY_HIGH;
  sConfigOC.OCFastMode = TIM_OCFAST_DISABLE;
  sConfigOC.OCIdleState = TIM_OCIDLESTATE_RESET;
  sConfigOC.OCNIdleState = TIM_OCNIDLESTATE_RESET;
  if (HAL_TIM_PWM_ConfigChannel(&htim15, &sConfigOC, TIM_CHANNEL_1) != HAL_OK)
  {
    Error_Handler();
  }
  if (HAL_TIM_PWM_ConfigChannel(&htim15, &sConfigOC, TIM_CHANNEL_2) != HAL_OK)
  {
    Error_Handler();
  }
  sBreakDeadTimeConfig.OffStateRunMode = TIM_OSSR_DISABLE;
  sBreakDeadTimeConfig.OffStateIDLEMode = TIM_OSSI_DISABLE;
  sBreakDeadTimeConfig.LockLevel = TIM_LOCKLEVEL_OFF;
  sBreakDeadTimeConfig.DeadTime = 0;
  sBreakDeadTimeConfig.BreakState = TIM_BREAK_DISABLE;
  sBreakDeadTimeConfig.BreakPolarity = TIM_BREAKPOLARITY_HIGH;
  sBreakDeadTimeConfig.BreakFilter = 0;
  sBreakDeadTimeConfig.AutomaticOutput = TIM_AUTOMATICOUTPUT_DISABLE;
  if (HAL_TIMEx_ConfigBreakDeadTime(&htim15, &sBreakDeadTimeConfig) != HAL_OK)
  {
    Error_Handler();
  }
  HAL_TIM_MspPostInit(&htim15);

}

static void MX_UART4_Init(void)
{

  huart4.Instance = UART4;
  huart4.Init.BaudRate = 115200;
  huart4.Init.WordLength = UART_WORDLENGTH_8B;
  huart4.Init.StopBits = UART_STOPBITS_1;
  huart4.Init.Parity = UART_PARITY_NONE;
  huart4.Init.Mode = UART_MODE_TX_RX;
  huart4.Init.HwFlowCtl = UART_HWCONTROL_NONE;
  huart4.Init.OverSampling = UART_OVERSAMPLING_16;
  huart4.Init.OneBitSampling = UART_ONE_BIT_SAMPLE_DISABLE;
  huart4.Init.ClockPrescaler = UART_PRESCALER_DIV1;
  huart4.AdvancedInit.AdvFeatureInit = UART_ADVFEATURE_NO_INIT;
  if (HAL_UART_Init(&huart4) != HAL_OK)
  {
    Error_Handler();
  }
  if (HAL_UARTEx_SetTxFifoThreshold(&huart4, UART_TXFIFO_THRESHOLD_1_8) != HAL_OK)
  {
    Error_Handler();
  }
  if (HAL_UARTEx_SetRxFifoThreshold(&huart4, UART_RXFIFO_THRESHOLD_1_8) != HAL_OK)
  {
    Error_Handler();
  }
  if (HAL_UARTEx_DisableFifoMode(&huart4) != HAL_OK)
  {
    Error_Handler();
  }

}

static void MX_UART8_Init(void)
{

  huart8.Instance = UART8;
  huart8.Init.BaudRate = 115200;
  huart8.Init.WordLength = UART_WORDLENGTH_8B;
  huart8.Init.StopBits = UART_STOPBITS_1;
  huart8.Init.Parity = UART_PARITY_NONE;
  huart8.Init.Mode = UART_MODE_TX_RX;
  huart8.Init.HwFlowCtl = UART_HWCONTROL_NONE;
  huart8.Init.OverSampling = UART_OVERSAMPLING_16;
  huart8.Init.OneBitSampling = UART_ONE_BIT_SAMPLE_DISABLE;
  huart8.Init.ClockPrescaler = UART_PRESCALER_DIV1;
  huart8.AdvancedInit.AdvFeatureInit = UART_ADVFEATURE_NO_INIT;
  if (HAL_UART_Init(&huart8) != HAL_OK)
  {
    Error_Handler();
  }
  if (HAL_UARTEx_SetTxFifoThreshold(&huart8, UART_TXFIFO_THRESHOLD_1_8) != HAL_OK)
  {
    Error_Handler();
  }
  if (HAL_UARTEx_SetRxFifoThreshold(&huart8, UART_RXFIFO_THRESHOLD_1_8) != HAL_OK)
  {
    Error_Handler();
  }
  if (HAL_UARTEx_DisableFifoMode(&huart8) != HAL_OK)
  {
    Error_Handler();
  }

}

static void MX_DMA_Init(void)
{

  /* DMA controller clock enable */
  __HAL_RCC_DMA1_CLK_ENABLE();

  /* DMA interrupt init */
  /* DMA1_Stream0_IRQn interrupt configuration */
  HAL_NVIC_SetPriority(DMA1_Stream0_IRQn, 5, 0);
  HAL_NVIC_EnableIRQ(DMA1_Stream0_IRQn);
  /* DMA1_Stream1_IRQn interrupt configuration */
  HAL_NVIC_SetPriority(DMA1_Stream1_IRQn, 5, 0);
  HAL_NVIC_EnableIRQ(DMA1_Stream1_IRQn);
  /* DMA1_Stream2_IRQn interrupt configuration */
  HAL_NVIC_SetPriority(DMA1_Stream2_IRQn, 5, 0);
  HAL_NVIC_EnableIRQ(DMA1_Stream2_IRQn);
  /* DMA1_Stream3_IRQn interrupt configuration */
  HAL_NVIC_SetPriority(DMA1_Stream3_IRQn, 5, 0);
  HAL_NVIC_EnableIRQ(DMA1_Stream3_IRQn);
  /* DMA1_Stream4_IRQn interrupt configuration */
  HAL_NVIC_SetPriority(DMA1_Stream4_IRQn, 5, 0);
  HAL_NVIC_EnableIRQ(DMA1_Stream4_IRQn);

}

static void MX_GPIO_Init(void)
{
  GPIO_InitTypeDef GPIO_InitStruct = {0};

  /* GPIO Ports Clock Enable */
  __HAL_RCC_GPIOE_CLK_ENABLE();
  __HAL_RCC_GPIOC_CLK_ENABLE();
  __HAL_RCC_GPIOH_CLK_ENABLE();
  __HAL_RCC_GPIOA_CLK_ENABLE();
  __HAL_RCC_GPIOB_CLK_ENABLE();
  __HAL_RCC_GPIOD_CLK_ENABLE();

  /*Configure GPIO pin Output Level */
  HAL_GPIO_WritePin(GPIOE, GPIO_PIN_3|GPIO_PIN_4|GPIO_PIN_7|GPIO_PIN_8
                          |GPIO_PIN_9|GPIO_PIN_10|GPIO_PIN_14|GPIO_PIN_15, GPIO_PIN_RESET);

  /*Configure GPIO pin Output Level */
  HAL_GPIO_WritePin(GPIOD, GPIO_PIN_8|GPIO_PIN_4|GPIO_PIN_5|GPIO_PIN_6, GPIO_PIN_RESET);

  /*Configure GPIO pin Output Level */
  HAL_GPIO_WritePin(GPIOA, GPIO_PIN_10, GPIO_PIN_RESET);

  /*Configure GPIO pins : PE2 PE12 */
  GPIO_InitStruct.Pin = GPIO_PIN_2|GPIO_PIN_12;
  GPIO_InitStruct.Mode = GPIO_MODE_INPUT;
  GPIO_InitStruct.Pull = GPIO_NOPULL;
  HAL_GPIO_Init(GPIOE, &GPIO_InitStruct);

  /*Configure GPIO pins : PE3 PE4 PE7 PE8
                           PE9 PE10 PE14 PE15 */
  GPIO_InitStruct.Pin = GPIO_PIN_3|GPIO_PIN_4|GPIO_PIN_7|GPIO_PIN_8
                          |GPIO_PIN_9|GPIO_PIN_10|GPIO_PIN_14|GPIO_PIN_15;
  GPIO_InitStruct.Mode = GPIO_MODE_OUTPUT_PP;
  GPIO_InitStruct.Pull = GPIO_NOPULL;
  GPIO_InitStruct.Speed = GPIO_SPEED_FREQ_LOW;
  HAL_GPIO_Init(GPIOE, &GPIO_InitStruct);

  /*Configure GPIO pins : PC13 PC14 PC15 */
  GPIO_InitStruct.Pin = GPIO_PIN_13|GPIO_PIN_14|GPIO_PIN_15;
  GPIO_InitStruct.Mode = GPIO_MODE_INPUT;
  GPIO_InitStruct.Pull = GPIO_NOPULL;
  HAL_GPIO_Init(GPIOC, &GPIO_InitStruct);

  /*Configure GPIO pins : PD8 PD4 PD5 PD6 */
  GPIO_InitStruct.Pin = GPIO_PIN_8|GPIO_PIN_4|GPIO_PIN_5|GPIO_PIN_6;
  GPIO_InitStruct.Mode = GPIO_MODE_OUTPUT_PP;
  GPIO_InitStruct.Pull = GPIO_NOPULL;
  GPIO_InitStruct.Speed = GPIO_SPEED_FREQ_LOW;
  HAL_GPIO_Init(GPIOD, &GPIO_InitStruct);

  /*Configure GPIO pins : PD9 PD10 PD2 */
  GPIO_InitStruct.Pin = GPIO_PIN_9|GPIO_PIN_10|GPIO_PIN_2;
  GPIO_InitStruct.Mode = GPIO_MODE_INPUT;
  GPIO_InitStruct.Pull = GPIO_NOPULL;
  HAL_GPIO_Init(GPIOD, &GPIO_InitStruct);

  /*Configure GPIO pin : PD11 */
  GPIO_InitStruct.Pin = GPIO_PIN_11;
  GPIO_InitStruct.Mode = GPIO_MODE_IT_RISING;
  GPIO_InitStruct.Pull = GPIO_NOPULL;
  HAL_GPIO_Init(GPIOD, &GPIO_InitStruct);

  /*Configure GPIO pins : PD13 PD14 PD15 */
  GPIO_InitStruct.Pin = GPIO_PIN_13|GPIO_PIN_14|GPIO_PIN_15;
  GPIO_InitStruct.Mode = GPIO_MODE_IT_RISING_FALLING;
  GPIO_InitStruct.Pull = GPIO_NOPULL;
  HAL_GPIO_Init(GPIOD, &GPIO_InitStruct);

  /*Configure GPIO pin : PA10 */
  GPIO_InitStruct.Pin = GPIO_PIN_10;
  GPIO_InitStruct.Mode = GPIO_MODE_OUTPUT_PP;
  GPIO_InitStruct.Pull = GPIO_NOPULL;
  GPIO_InitStruct.Speed = GPIO_SPEED_FREQ_LOW;
  HAL_GPIO_Init(GPIOA, &GPIO_InitStruct);

  /*Configure GPIO pin : PA15 */
  GPIO_InitStruct.Pin = GPIO_PIN_15;
  GPIO_InitStruct.Mode = GPIO_MODE_INPUT;
  GPIO_InitStruct.Pull = GPIO_NOPULL;
  HAL_GPIO_Init(GPIOA, &GPIO_InitStruct);

  /*Configure GPIO pins : PB4 PB6 */
  GPIO_InitStruct.Pin = GPIO_PIN_4|GPIO_PIN_6;
  GPIO_InitStruct.Mode = GPIO_MODE_ANALOG;
  GPIO_InitStruct.Pull = GPIO_NOPULL;
  HAL_GPIO_Init(GPIOB, &GPIO_InitStruct);

  /* EXTI interrupt init*/
  HAL_NVIC_SetPriority(EXTI15_10_IRQn, 5, 0);
  HAL_NVIC_EnableIRQ(EXTI15_10_IRQn);

}

void StartDefaultTask(void *argument)
{
  for(;;)
  {
    osDelay(1);
  }
}

void StartAcquisition(void *argument)
{
  for(;;)
  {
    osDelay(1);
  }
}

void StartComms(void *argument)
{
  for(;;)
  {
    osDelay(1);
  }
}

void StartControl(void *argument)
{
  for(;;)
  {
    osDelay(1);
  }
}

void StartGUI(void *argument)
{
  /* USER CODE BEGIN StartGUI */
  gui_init();
  for (;;) {
    gui_task_run();
    osDelay(5); /* yield CPU; LVGL self-throttles to ~30 fps */
  }
  /* USER CODE END StartGUI */
}

 /* MPU Configuration */

void MPU_Config(void)
{
  MPU_Region_InitTypeDef MPU_InitStruct = {0};

  /* Disables the MPU */
  HAL_MPU_Disable();

  /** Initializes and configures the Region and the memory to be protected
  */
  MPU_InitStruct.Enable = MPU_REGION_ENABLE;
  MPU_InitStruct.Number = MPU_REGION_NUMBER0;
  MPU_InitStruct.BaseAddress = 0x0;
  MPU_InitStruct.Size = MPU_REGION_SIZE_4GB;
  MPU_InitStruct.SubRegionDisable = 0x87;
  MPU_InitStruct.TypeExtField = MPU_TEX_LEVEL0;
  MPU_InitStruct.AccessPermission = MPU_REGION_NO_ACCESS;
  MPU_InitStruct.DisableExec = MPU_INSTRUCTION_ACCESS_DISABLE;
  MPU_InitStruct.IsShareable = MPU_ACCESS_SHAREABLE;
  MPU_InitStruct.IsCacheable = MPU_ACCESS_NOT_CACHEABLE;
  MPU_InitStruct.IsBufferable = MPU_ACCESS_NOT_BUFFERABLE;

  HAL_MPU_ConfigRegion(&MPU_InitStruct);
  /* Enables the MPU */
  HAL_MPU_Enable(MPU_PRIVILEGED_DEFAULT);

}

void HAL_TIM_PeriodElapsedCallback(TIM_HandleTypeDef *htim)
{
  if (htim->Instance == TIM6)
  {
    HAL_IncTick();
  }
  /* USER CODE BEGIN Callback 1 */
  if (htim->Instance == TIM7)
  {
    tim7_PeriodElapsedCallback_action();
  }
  /* USER CODE END Callback 1 */
}

void Error_Handler(void)
{
  __disable_irq();
  while (1)
  {
  }
}
